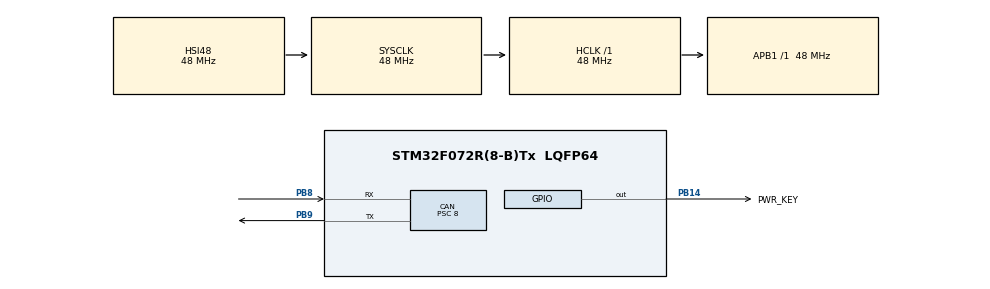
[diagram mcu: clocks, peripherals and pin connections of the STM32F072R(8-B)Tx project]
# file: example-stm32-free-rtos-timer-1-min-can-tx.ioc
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CAN.ABOM=DISABLE
CAN.AWUM=DISABLE
CAN.BS1=CAN_BS1_3TQ
CAN.BS2=CAN_BS2_8TQ
CAN.CalculateBaudRate=500000
CAN.CalculateTimeBit=2000
CAN.CalculateTimeQuantum=166.66666666666666
CAN.NART=DISABLE
CAN.Prescaler=8
CAN.SJW=CAN_SJW_1TQ
FREERTOS.Tasks01=TransmitCanMsg,2,128,vReceiveCanData,Default,NULL,Dynamic,NULL,NULL
FREERTOS.Timers01=myTimer01,myTimerCallback01,osTimerOnce,Default,NULL,Dynamic,NULL
FREERTOS.configTIMER_TASK_PRIORITY=6
FREERTOS.configUSE_NEWLIB_REENTRANT=1
FREERTOS.configUSE_TIMERS=1
Mcu.Family=STM32F0
Mcu.Name=STM32F072R(8-B)Tx
Mcu.Package=LQFP64
NVIC.CEC_CAN_IRQn=true\:3\:0\:false\:false\:true\:true\:true\:true\:true
NVIC.TIM6_DAC_IRQn=true\:3\:0\:false\:false\:true\:false\:false\:true\:true
NVIC.TimeBase=TIM6_DAC_IRQn
NVIC.TimeBaseIP=TIM6
PB14.GPIO_Label=PWR_KEY
PB14.Signal=GPIO_Output
PB8.Mode=CAN_Activate
PB8.Signal=CAN_RX
PB9.Mode=CAN_Activate
PB9.Signal=CAN_TX
ProjectManager.HeapSize=0x200
ProjectManager.StackSize=0x400
ProjectManager.TargetToolchain=STM32CubeIDE
RCC.AHBFreq_Value=48000000
RCC.APB1Freq_Value=48000000
RCC.APB1TimFreq_Value=48000000
RCC.HCLKFreq_Value=48000000
RCC.PLLMUL=RCC_PLL_MUL8
RCC.SYSCLKFreq_VALUE=48000000
RCC.SYSCLKSource=RCC_SYSCLKSOURCE_HSI48
RCC.USBFreq_Value=48000000
VP_FREERTOS_VS_CMSIS_V1.Mode=CMSIS_V1
VP_SYS_VS_tim6.Mode=TIM6
board=custom

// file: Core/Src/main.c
/* USER CODE BEGIN Header */
/**
  ******************************************************************************
  * @file           : main.c
  * @brief          : Main program body
  ******************************************************************************
  * @attention
  *
  * Copyright (c) 2022 STMicroelectronics.
  * All rights reserved.
  *
  * This software is licensed under terms that can be found in the LICENSE file
  * in the root directory of this software component.
  * If no LICENSE file comes with this software, it is provided AS-IS.
  *
  ******************************************************************************
  */
/* USER CODE END Header */
#include "main.h"
#include "cmsis_os.h"

CAN_HandleTypeDef hcan;

osThreadId TransmitCanMsgHandle;
osTimerId myTimer01Handle;

void SystemClock_Config(void);
static void MX_GPIO_Init(void);
static void MX_CAN_Init(void);
void vReceiveCanData(void const * argument);
void myTimerCallback01(void const * argument);

/* USER CODE BEGIN 0 */
CAN_TxHeaderTypeDef   TxHeader;
uint8_t               TxData[8];
uint32_t              TxMailbox;
uint16_t              Can_msg_id[5]={0x350,0x351,0x352,0x367,0x650};
static uint64_t       CanTxCount;
static uint8_t        CanMsgStopTx;
/* USER CODE END 0 */

int main(void)
{

  /* MCU Configuration--------------------------------------------------------*/

  /* Reset of all peripherals, Initializes the Flash interface and the Systick. */
  HAL_Init();

  /* Configure the system clock */
  SystemClock_Config();

  /* Initialize all configured peripherals */
  MX_GPIO_Init();
  MX_CAN_Init();

  /* Create the timer(s) */
  /* definition and creation of myTimer01 */
  osTimerDef(myTimer01, myTimerCallback01);
  myTimer01Handle = osTimerCreate(osTimer(myTimer01), osTimerOnce, NULL);

  /* Create the thread(s) */
  /* definition and creation of TransmitCanMsg */
  osThreadDef(TransmitCanMsg, vReceiveCanData, osPriorityHigh, 0, 128);
  TransmitCanMsgHandle = osThreadCreate(osThread(TransmitCanMsg), NULL);

  /* Start scheduler */
  osKernelStart();

  /* We should never get here as control is now taken by the scheduler */
  /* Infinite loop */
  while (1)
  {

  }
}

void SystemClock_Config(void)
{
  RCC_OscInitTypeDef RCC_OscInitStruct = {0};
  RCC_ClkInitTypeDef RCC_ClkInitStruct = {0};

  /** Initializes the RCC Oscillators according to the specified parameters
  * in the RCC_OscInitTypeDef structure.
  */
  RCC_OscInitStruct.OscillatorType = RCC_OSCILLATORTYPE_HSI48;
  RCC_OscInitStruct.HSI48State = RCC_HSI48_ON;
  RCC_OscInitStruct.PLL.PLLState = RCC_PLL_NONE;
  if (HAL_RCC_OscConfig(&RCC_OscInitStruct) != HAL_OK)
  {
    Error_Handler();
  }

  /** Initializes the CPU, AHB and APB buses clocks
  */
  RCC_ClkInitStruct.ClockType = RCC_CLOCKTYPE_HCLK|RCC_CLOCKTYPE_SYSCLK
                              |RCC_CLOCKTYPE_PCLK1;
  RCC_ClkInitStruct.SYSCLKSource = RCC_SYSCLKSOURCE_HSI48;
  RCC_ClkInitStruct.AHBCLKDivider = RCC_SYSCLK_DIV1;
  RCC_ClkInitStruct.APB1CLKDivider = RCC_HCLK_DIV1;

  if (HAL_RCC_ClockConfig(&RCC_ClkInitStruct, FLASH_LATENCY_1) != HAL_OK)
  {
    Error_Handler();
  }
}

static void MX_CAN_Init(void)
{

  hcan.Instance = CAN;
  hcan.Init.Prescaler = 8;
  hcan.Init.Mode = CAN_MODE_NORMAL;
  hcan.Init.SyncJumpWidth = CAN_SJW_1TQ;
  hcan.Init.TimeSeg1 = CAN_BS1_3TQ;
  hcan.Init.TimeSeg2 = CAN_BS2_8TQ;
  hcan.Init.TimeTriggeredMode = DISABLE;
  hcan.Init.AutoBusOff = DISABLE;
  hcan.Init.AutoWakeUp = DISABLE;
  hcan.Init.AutoRetransmission = DISABLE;
  hcan.Init.ReceiveFifoLocked = DISABLE;
  hcan.Init.TransmitFifoPriority = DISABLE;
  if (HAL_CAN_Init(&hcan) != HAL_OK)
  {
    Error_Handler();
  }

}

static void MX_GPIO_Init(void)
{
  GPIO_InitTypeDef GPIO_InitStruct = {0};

  /* GPIO Ports Clock Enable */
  __HAL_RCC_GPIOB_CLK_ENABLE();

  /*Configure GPIO pin Output Level */
  HAL_GPIO_WritePin(PWR_KEY_GPIO_Port, PWR_KEY_Pin, GPIO_PIN_RESET);

  /*Configure GPIO pin : PWR_KEY_Pin */
  GPIO_InitStruct.Pin = PWR_KEY_Pin;
  GPIO_InitStruct.Mode = GPIO_MODE_OUTPUT_PP;
  GPIO_InitStruct.Pull = GPIO_NOPULL;
  GPIO_InitStruct.Speed = GPIO_SPEED_FREQ_LOW;
  HAL_GPIO_Init(PWR_KEY_GPIO_Port, &GPIO_InitStruct);

}

/* USER CODE BEGIN 4 */
void HAL_CAN_TxMailbox0CompleteCallback(CAN_HandleTypeDef *hcan)
{
  //No. of CAN MSG sent count
  CanTxCount++;
}
/* USER CODE END 4 */

void vReceiveCanData(void const * argument)
{
  /* USER CODE BEGIN 5 */

  uint8_t TxMsgCnt=0;

  TxHeader.IDE = CAN_ID_STD;
  TxHeader.StdId = Can_msg_id[0];
  TxHeader.RTR = CAN_RTR_DATA;
  TxHeader.DLC = 8;

  TxData[0] = 0x88;
  TxData[1] = 0x99;
  TxData[2] = 0xAA;
  TxData[3] = 0xBB;
  TxData[4] = 0xCC;
  TxData[5] = 0xDD;
  TxData[6] = 0xEE;
  TxData[7] = 0xFF;

  /* 60 second free-rtos timer start */
  osTimerStart(myTimer01Handle, 60000); //60000=60*1000ms=60sec=1Minute

  /* Infinite loop used to sent CAN messages till timer expired */
  for(;;)
  {
    for(TxMsgCnt=0; (CanMsgStopTx==0 && TxMsgCnt<5); TxMsgCnt++)
    {
      TxHeader.StdId=Can_msg_id[TxMsgCnt];
      HAL_CAN_AddTxMessage(&hcan, &TxHeader, TxData, &TxMailbox);
    }
  }
  /* USER CODE END 5 */
}

/* myTimerCallback01 function */
void myTimerCallback01(void const * argument)
{
  /* USER CODE BEGIN myTimerCallback01 */
  CanMsgStopTx=1;
  /* USER CODE END myTimerCallback01 */
}

void HAL_TIM_PeriodElapsedCallback(TIM_HandleTypeDef *htim)
{
  if (htim->Instance == TIM6) {
    HAL_IncTick();
  }
}

void Error_Handler(void)
{
  __disable_irq();
  while (1)
  {
  }
}
